VERSION ""

NS_ :

BS_:

BU_: Main_Module Torque_Vector Driveline Precharge Dashboard Steering Acceleration bootloader BMS_LV TESTER DAQ Precharge BMS1 TEST_NODE TEST_NODE_2 DAQ

BO_ 2214598913 main_hb: 2 Main_Module
 SG_ precharge_state : 8|1@1+ (1,0) [0|0] "" Vector__XXX
 SG_ car_state : 0|8@1+ (1,0) [0|0] "" Vector__XXX

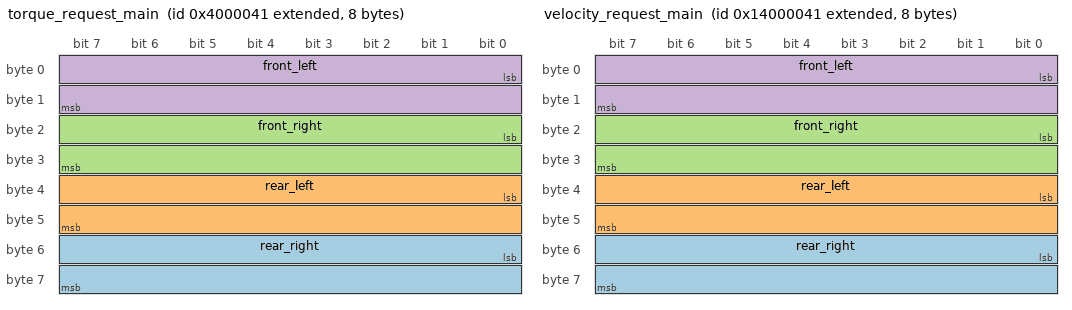
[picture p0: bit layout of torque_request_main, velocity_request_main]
BO_ 2214592577 torque_request_main: 8 Main_Module
 SG_ rear_right : 48|16@1- (1,0) [0|0] "" Vector__XXX
 SG_ rear_left : 32|16@1- (1,0) [0|0] "" Vector__XXX
 SG_ front_right : 16|16@1- (1,0) [0|0] "" Vector__XXX
 SG_ front_left : 0|16@1- (1,0) [0|0] "" Vector__XXX

BO_ 2483028033 velocity_request_main: 8 Main_Module
 SG_ rear_right : 48|16@1- (1,0) [0|0] "" Vector__XXX
 SG_ rear_left : 32|16@1- (1,0) [0|0] "" Vector__XXX
 SG_ front_right : 16|16@1- (1,0) [0|0] "" Vector__XXX
 SG_ front_left : 0|16@1- (1,0) [0|0] "" Vector__XXX

BO_ 2550136769 daq_response_MAIN_MODULE: 8 Main_Module
 SG_ daq_response : 0|64@1+ (1,0) [0|0] "" Vector__XXX

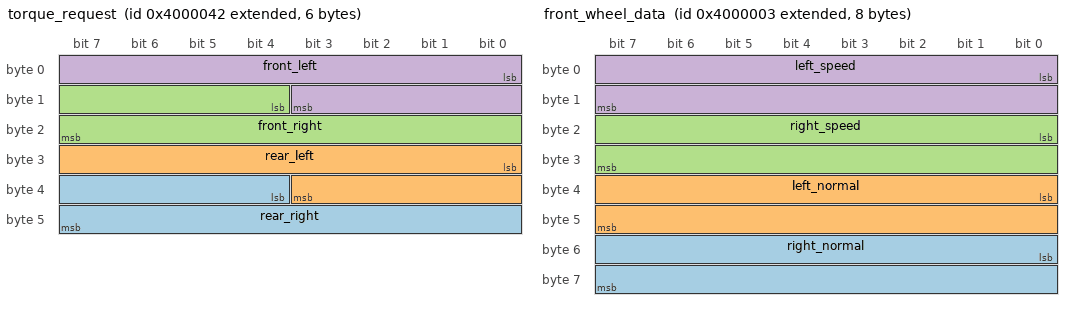
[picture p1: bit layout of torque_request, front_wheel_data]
BO_ 2214592578 torque_request: 6 Torque_Vector
 SG_ rear_right : 36|12@1+ (1,0) [0|0] "" Vector__XXX
 SG_ rear_left : 24|12@1+ (1,0) [0|0] "" Vector__XXX
 SG_ front_right : 12|12@1+ (1,0) [0|0] "" Vector__XXX
 SG_ front_left : 0|12@1+ (1,0) [0|0] "" Vector__XXX

BO_ 2147490050 bitstream_flash_status: 1 Torque_Vector
 SG_ flash_timeout_rx : 1|1@1+ (1,0) [0|0] "" Vector__XXX
 SG_ flash_success : 0|1@1+ (1,0) [0|0] "" Vector__XXX

BO_ 2214598915 front_driveline_hb: 2 Driveline
 SG_ front_right_motor : 8|8@1+ (1,0) [0|0] "" Vector__XXX
 SG_ front_left_motor : 0|8@1+ (1,0) [0|0] "" Vector__XXX

BO_ 2214598979 rear_driveline_hb: 2 Driveline
 SG_ rear_right_motor : 8|8@1+ (1,0) [0|0] "" Vector__XXX
 SG_ rear_left_motor : 0|8@1+ (1,0) [0|0] "" Vector__XXX

BO_ 2214592515 front_wheel_data: 8 Driveline
 SG_ right_normal : 48|16@1+ (1,0) [0|0] "" Vector__XXX
 SG_ left_normal : 32|16@1+ (1,0) [0|0] "" Vector__XXX
 SG_ right_speed : 16|16@1+ (1,0) [0|0] "kphx100" Vector__XXX
 SG_ left_speed : 0|16@1+ (1,0) [0|0] "kphx100" Vector__XXX

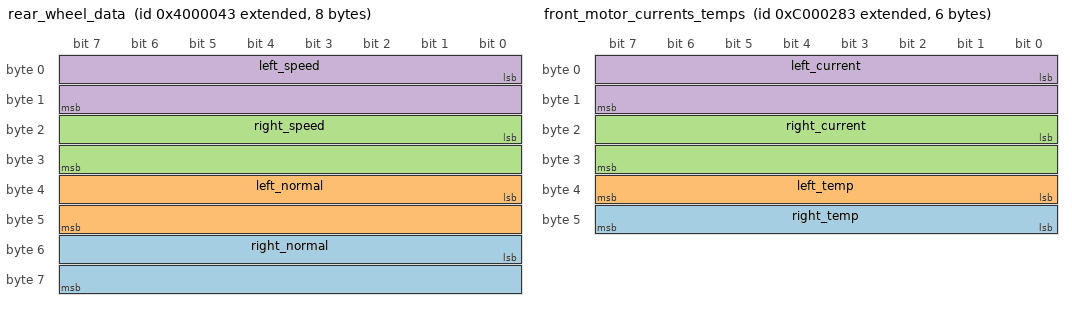
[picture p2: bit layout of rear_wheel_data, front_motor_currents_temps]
BO_ 2214592579 rear_wheel_data: 8 Driveline
 SG_ right_normal : 48|16@1+ (1,0) [0|0] "" Vector__XXX
 SG_ left_normal : 32|16@1+ (1,0) [0|0] "" Vector__XXX
 SG_ right_speed : 16|16@1+ (1,0) [0|0] "kphx100" Vector__XXX
 SG_ left_speed : 0|16@1+ (1,0) [0|0] "kphx100" Vector__XXX

BO_ 2348810883 front_motor_currents_temps: 6 Driveline
 SG_ right_temp : 40|8@1+ (1,0) [0|0] "C" Vector__XXX
 SG_ left_temp : 32|8@1+ (1,0) [0|0] "C" Vector__XXX
 SG_ right_current : 16|16@1+ (1,0) [0|0] "Ampx10" Vector__XXX
 SG_ left_current : 0|16@1+ (1,0) [0|0] "Ampx10" Vector__XXX

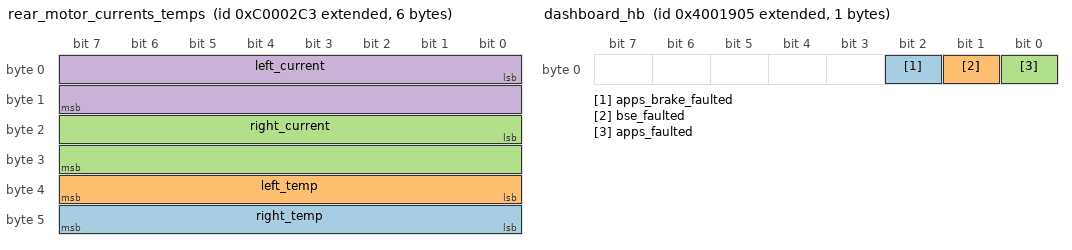
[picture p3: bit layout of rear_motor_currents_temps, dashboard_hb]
BO_ 2348810947 rear_motor_currents_temps: 6 Driveline
 SG_ right_temp : 40|8@1+ (1,0) [0|0] "C" Vector__XXX
 SG_ left_temp : 32|8@1+ (1,0) [0|0] "C" Vector__XXX
 SG_ right_current : 16|16@1+ (1,0) [0|0] "Ampx10" Vector__XXX
 SG_ left_current : 0|16@1+ (1,0) [0|0] "Ampx10" Vector__XXX

BO_ 2483028739 front_motor_init: 2 Driveline
 SG_ front_right_init : 8|8@1+ (1,0) [0|0] "" Vector__XXX
 SG_ front_left_init : 0|8@1+ (1,0) [0|0] "" Vector__XXX

BO_ 2483028803 rear_motor_init: 2 Driveline
 SG_ rear_right_init : 8|8@1+ (1,0) [0|0] "" Vector__XXX
 SG_ rear_left_init : 0|8@1+ (1,0) [0|0] "" Vector__XXX

BO_ 2281734148 test_precharge_msg: 1 Precharge
 SG_ test_precharge_sig : 0|8@1+ (1,0) [0|0] "" Vector__XXX

BO_ 2483028613 raw_throttle_brake: 3 Dashboard
 SG_ brake : 12|12@1+ (1,0) [0|0] "" Vector__XXX
 SG_ throttle : 0|12@1+ (1,0) [0|0] "" Vector__XXX

BO_ 2214592517 start_button: 1 Dashboard
 SG_ start : 0|1@1+ (1,0) [0|0] "" Vector__XXX

BO_ 2214598917 dashboard_hb: 1 Dashboard
 SG_ apps_brake_faulted : 2|1@1+ (1,0) [0|0] "" Vector__XXX
 SG_ bse_faulted : 1|1@1+ (1,0) [0|0] "" Vector__XXX
 SG_ apps_faulted : 0|1@1+ (1,0) [0|0] "" Vector__XXX

BO_ 2550136773 daq_response_DASHBOARD: 8 Dashboard
 SG_ daq_response : 0|64@1+ (1,0) [0|0] "" Vector__XXX

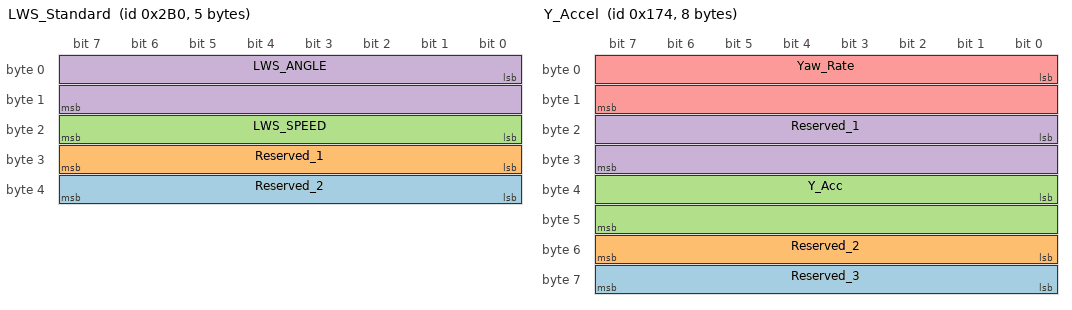
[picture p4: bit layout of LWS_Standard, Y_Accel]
BO_ 688 LWS_Standard: 5 Steering
 SG_ Reserved_2 : 32|8@1+ (1,0) [0|0] "" Vector__XXX
 SG_ Reserved_1 : 24|8@1+ (1,0) [0|0] "" Vector__XXX
 SG_ LWS_SPEED : 16|8@1+ (4,0) [0|0] "°/s" Vector__XXX
 SG_ LWS_ANGLE : 0|16@1- (0.1,0) [0|0] "°" Vector__XXX

BO_ 372 Y_Accel: 8 Acceleration
 SG_ Reserved_3 : 56|8@1+ (1,0) [0|0] "" Vector__XXX
 SG_ Reserved_2 : 48|8@1+ (1,0) [0|0] "" Vector__XXX
 SG_ Y_Acc : 32|16@1+ (0.0001274,-4.1746432) [0|0] "g" Vector__XXX
 SG_ Reserved_1 : 16|16@1+ (1,0) [0|0] "" Vector__XXX
 SG_ Yaw_Rate : 0|16@1+ (0.005,-163.84) [0|0] "°/s" Vector__XXX

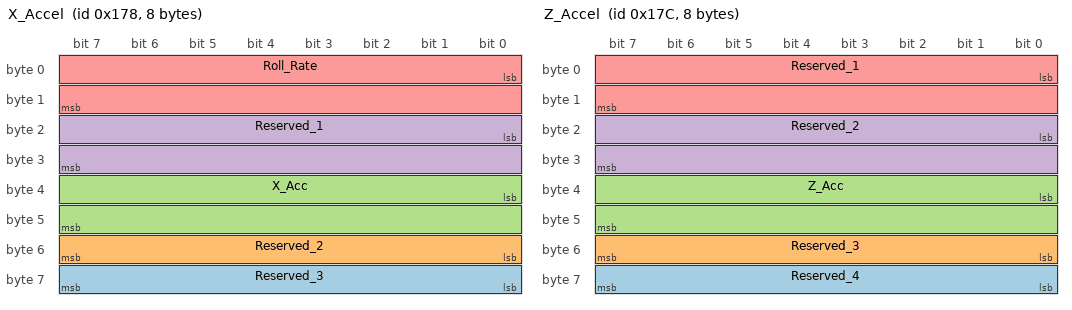
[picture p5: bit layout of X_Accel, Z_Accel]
BO_ 376 X_Accel: 8 Acceleration
 SG_ Reserved_3 : 56|8@1+ (1,0) [0|0] "" Vector__XXX
 SG_ Reserved_2 : 48|8@1+ (1,0) [0|0] "" Vector__XXX
 SG_ X_Acc : 32|16@1+ (0.0001274,-4.1746432) [0|0] "g" Vector__XXX
 SG_ Reserved_1 : 16|16@1+ (1,0) [0|0] "" Vector__XXX
 SG_ Roll_Rate : 0|16@1+ (0.005,-163.84) [0|0] "°/s" Vector__XXX

BO_ 380 Z_Accel: 8 Acceleration
 SG_ Reserved_4 : 56|8@1+ (1,0) [0|0] "" Vector__XXX
 SG_ Reserved_3 : 48|8@1+ (1,0) [0|0] "" Vector__XXX
 SG_ Z_Acc : 32|16@1+ (0.0001274,-4.1746432) [0|0] "g" Vector__XXX
 SG_ Reserved_2 : 16|16@1+ (1,0) [0|0] "" Vector__XXX
 SG_ Reserved_1 : 0|16@1+ (1,0) [0|0] "" Vector__XXX

BO_ 2214912572 mainmodule_bl_resp: 5 bootloader
 SG_ data : 8|32@1+ (1,0) [0|0] "" Vector__XXX
 SG_ cmd : 0|8@1+ (1,0) [0|0] "" Vector__XXX

BO_ 2214912636 dashboard_bl_resp: 5 bootloader
 SG_ data : 8|32@1+ (1,0) [0|0] "" Vector__XXX
 SG_ cmd : 0|8@1+ (1,0) [0|0] "" Vector__XXX

BO_ 2214912700 torquevector_bl_resp: 5 bootloader
 SG_ data : 8|32@1+ (1,0) [0|0] "" Vector__XXX
 SG_ cmd : 0|8@1+ (1,0) [0|0] "" Vector__XXX

BO_ 2214912764 driveline_f_bl_resp: 5 bootloader
 SG_ data : 8|32@1+ (1,0) [0|0] "" Vector__XXX
 SG_ cmd : 0|8@1+ (1,0) [0|0] "" Vector__XXX

BO_ 2214912828 driveline_r_bl_resp: 5 bootloader
 SG_ data : 8|32@1+ (1,0) [0|0] "" Vector__XXX
 SG_ cmd : 0|8@1+ (1,0) [0|0] "" Vector__XXX

BO_ 2214912892 precharge_bl_resp: 5 bootloader
 SG_ data : 8|32@1+ (1,0) [0|0] "" Vector__XXX
 SG_ cmd : 0|8@1+ (1,0) [0|0] "" Vector__XXX

BO_ 2214912956 bms_a_bl_resp: 5 bootloader
 SG_ data : 8|32@1+ (1,0) [0|0] "" Vector__XXX
 SG_ cmd : 0|8@1+ (1,0) [0|0] "" Vector__XXX

BO_ 2214913020 bms_b_bl_resp: 5 bootloader
 SG_ data : 8|32@1+ (1,0) [0|0] "" Vector__XXX
 SG_ cmd : 0|8@1+ (1,0) [0|0] "" Vector__XXX

BO_ 2214913084 bms_c_bl_resp: 5 bootloader
 SG_ data : 8|32@1+ (1,0) [0|0] "" Vector__XXX
 SG_ cmd : 0|8@1+ (1,0) [0|0] "" Vector__XXX

BO_ 2214913148 bms_d_bl_resp: 5 bootloader
 SG_ data : 8|32@1+ (1,0) [0|0] "" Vector__XXX
 SG_ cmd : 0|8@1+ (1,0) [0|0] "" Vector__XXX

BO_ 2214913212 bms_e_bl_resp: 5 bootloader
 SG_ data : 8|32@1+ (1,0) [0|0] "" Vector__XXX
 SG_ cmd : 0|8@1+ (1,0) [0|0] "" Vector__XXX

BO_ 2214913276 bms_f_bl_resp: 5 bootloader
 SG_ data : 8|32@1+ (1,0) [0|0] "" Vector__XXX
 SG_ cmd : 0|8@1+ (1,0) [0|0] "" Vector__XXX

BO_ 2214913340 bms_g_bl_resp: 5 bootloader
 SG_ data : 8|32@1+ (1,0) [0|0] "" Vector__XXX
 SG_ cmd : 0|8@1+ (1,0) [0|0] "" Vector__XXX

BO_ 2214913404 bms_h_bl_resp: 5 bootloader
 SG_ data : 8|32@1+ (1,0) [0|0] "" Vector__XXX
 SG_ cmd : 0|8@1+ (1,0) [0|0] "" Vector__XXX

BO_ 2214913468 bms_i_bl_resp: 5 bootloader
 SG_ data : 8|32@1+ (1,0) [0|0] "" Vector__XXX
 SG_ cmd : 0|8@1+ (1,0) [0|0] "" Vector__XXX

BO_ 2214913532 bms_j_bl_resp: 5 bootloader
 SG_ data : 8|32@1+ (1,0) [0|0] "" Vector__XXX
 SG_ cmd : 0|8@1+ (1,0) [0|0] "" Vector__XXX

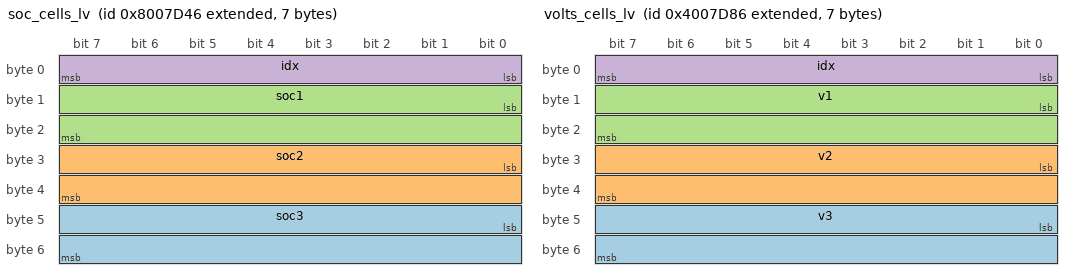
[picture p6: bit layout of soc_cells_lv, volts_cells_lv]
BO_ 2281733446 soc_cells_lv: 7 BMS_LV
 SG_ soc3 : 40|16@1+ (1,0) [0|0] "" Vector__XXX
 SG_ soc2 : 24|16@1+ (1,0) [0|0] "" Vector__XXX
 SG_ soc1 : 8|16@1+ (1,0) [0|0] "" Vector__XXX
 SG_ idx : 0|8@1+ (1,0) [0|0] "" Vector__XXX

BO_ 2214624646 volts_cells_lv: 7 BMS_LV
 SG_ v3 : 40|16@1+ (1,0) [0|0] "" Vector__XXX
 SG_ v2 : 24|16@1+ (1,0) [0|0] "" Vector__XXX
 SG_ v1 : 8|16@1+ (1,0) [0|0] "" Vector__XXX
 SG_ idx : 0|8@1+ (1,0) [0|0] "" Vector__XXX

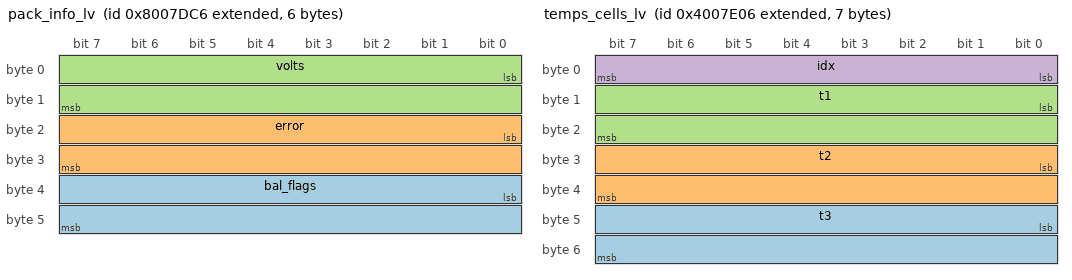
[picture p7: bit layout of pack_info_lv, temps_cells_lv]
BO_ 2281733574 pack_info_lv: 6 BMS_LV
 SG_ bal_flags : 32|16@1+ (1,0) [0|0] "" Vector__XXX
 SG_ error : 16|16@1+ (1,0) [0|0] "" Vector__XXX
 SG_ volts : 0|16@1+ (1,0) [0|0] "" Vector__XXX

BO_ 2214624774 temps_cells_lv: 7 BMS_LV
 SG_ t3 : 40|16@1+ (1,0) [0|0] "" Vector__XXX
 SG_ t2 : 24|16@1+ (1,0) [0|0] "" Vector__XXX
 SG_ t1 : 8|16@1+ (1,0) [0|0] "" Vector__XXX
 SG_ idx : 0|8@1+ (1,0) [0|0] "" Vector__XXX

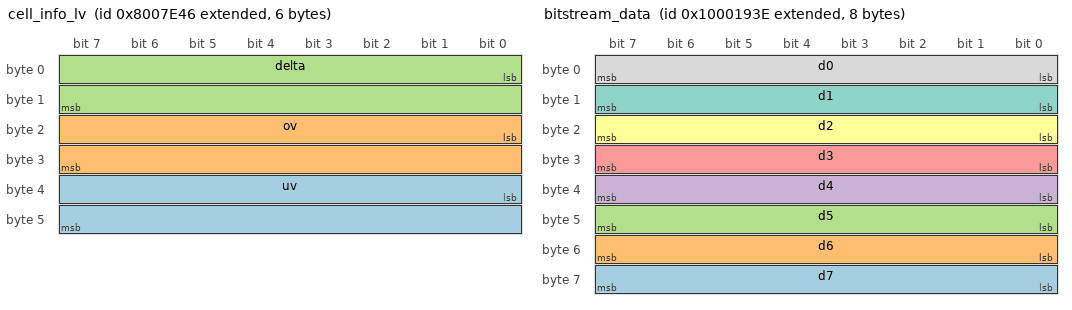
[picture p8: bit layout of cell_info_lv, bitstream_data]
BO_ 2281733702 cell_info_lv: 6 BMS_LV
 SG_ uv : 32|16@1+ (1,0) [0|0] "" Vector__XXX
 SG_ ov : 16|16@1+ (1,0) [0|0] "" Vector__XXX
 SG_ delta : 0|16@1+ (1,0) [0|0] "" Vector__XXX

BO_ 2214624902 power_lim_lv: 4 BMS_LV
 SG_ chg_lim : 16|16@1+ (1,0) [0|0] "" Vector__XXX
 SG_ disch_lim : 0|16@1+ (1,0) [0|0] "" Vector__XXX

BO_ 2282341438 bootloader_request_reset: 1 TESTER
 SG_ node : 0|8@1+ (1,0) [0|0] "" Vector__XXX

BO_ 2415925566 bitstream_data: 8 TESTER
 SG_ d7 : 56|8@1+ (1,0) [0|0] "" Vector__XXX
 SG_ d6 : 48|8@1+ (1,0) [0|0] "" Vector__XXX
 SG_ d5 : 40|8@1+ (1,0) [0|0] "" Vector__XXX
 SG_ d4 : 32|8@1+ (1,0) [0|0] "" Vector__XXX
 SG_ d3 : 24|8@1+ (1,0) [0|0] "" Vector__XXX
 SG_ d2 : 16|8@1+ (1,0) [0|0] "" Vector__XXX
 SG_ d1 : 8|8@1+ (1,0) [0|0] "" Vector__XXX
 SG_ d0 : 0|8@1+ (1,0) [0|0] "" Vector__XXX

BO_ 2415925630 bitstream_request: 5 TESTER
 SG_ download_size : 1|32@1+ (1,0) [0|0] "" Vector__XXX
 SG_ download_request : 0|1@1+ (1,0) [0|0] "" Vector__XXX

BO_ 2215232574 mainmodule_bl_cmd: 5 TESTER
 SG_ data : 8|32@1+ (1,0) [0|0] "" Vector__XXX
 SG_ cmd : 0|8@1+ (1,0) [0|0] "" Vector__XXX

BO_ 2215232638 dashboard_bl_cmd: 5 TESTER
 SG_ data : 8|32@1+ (1,0) [0|0] "" Vector__XXX
 SG_ cmd : 0|8@1+ (1,0) [0|0] "" Vector__XXX

BO_ 2215232702 torquevector_bl_cmd: 5 TESTER
 SG_ data : 8|32@1+ (1,0) [0|0] "" Vector__XXX
 SG_ cmd : 0|8@1+ (1,0) [0|0] "" Vector__XXX

BO_ 2215232766 driveline_f_bl_cmd: 5 TESTER
 SG_ data : 8|32@1+ (1,0) [0|0] "" Vector__XXX
 SG_ cmd : 0|8@1+ (1,0) [0|0] "" Vector__XXX

BO_ 2215232830 driveline_r_bl_cmd: 5 TESTER
 SG_ data : 8|32@1+ (1,0) [0|0] "" Vector__XXX
 SG_ cmd : 0|8@1+ (1,0) [0|0] "" Vector__XXX

BO_ 2215232894 precharge_bl_cmd: 5 TESTER
 SG_ data : 8|32@1+ (1,0) [0|0] "" Vector__XXX
 SG_ cmd : 0|8@1+ (1,0) [0|0] "" Vector__XXX

BO_ 2215232958 bms_a_bl_cmd: 5 TESTER
 SG_ data : 8|32@1+ (1,0) [0|0] "" Vector__XXX
 SG_ cmd : 0|8@1+ (1,0) [0|0] "" Vector__XXX

BO_ 2215233022 bms_b_bl_cmd: 5 TESTER
 SG_ data : 8|32@1+ (1,0) [0|0] "" Vector__XXX
 SG_ cmd : 0|8@1+ (1,0) [0|0] "" Vector__XXX

BO_ 2215233086 bms_c_bl_cmd: 5 TESTER
 SG_ data : 8|32@1+ (1,0) [0|0] "" Vector__XXX
 SG_ cmd : 0|8@1+ (1,0) [0|0] "" Vector__XXX

BO_ 2215233150 bms_d_bl_cmd: 5 TESTER
 SG_ data : 8|32@1+ (1,0) [0|0] "" Vector__XXX
 SG_ cmd : 0|8@1+ (1,0) [0|0] "" Vector__XXX

BO_ 2215233214 bms_e_bl_cmd: 5 TESTER
 SG_ data : 8|32@1+ (1,0) [0|0] "" Vector__XXX
 SG_ cmd : 0|8@1+ (1,0) [0|0] "" Vector__XXX

BO_ 2215233278 bms_f_bl_cmd: 5 TESTER
 SG_ data : 8|32@1+ (1,0) [0|0] "" Vector__XXX
 SG_ cmd : 0|8@1+ (1,0) [0|0] "" Vector__XXX

BO_ 2215233342 bms_g_bl_cmd: 5 TESTER
 SG_ data : 8|32@1+ (1,0) [0|0] "" Vector__XXX
 SG_ cmd : 0|8@1+ (1,0) [0|0] "" Vector__XXX

BO_ 2215233406 bms_h_bl_cmd: 5 TESTER
 SG_ data : 8|32@1+ (1,0) [0|0] "" Vector__XXX
 SG_ cmd : 0|8@1+ (1,0) [0|0] "" Vector__XXX

BO_ 2215233470 bms_i_bl_cmd: 5 TESTER
 SG_ data : 8|32@1+ (1,0) [0|0] "" Vector__XXX
 SG_ cmd : 0|8@1+ (1,0) [0|0] "" Vector__XXX

BO_ 2215233534 bms_j_bl_cmd: 5 TESTER
 SG_ data : 8|32@1+ (1,0) [0|0] "" Vector__XXX
 SG_ cmd : 0|8@1+ (1,0) [0|0] "" Vector__XXX

BO_ 2483028082 daq_command_MAIN_MODULE: 8 DAQ
 SG_ daq_command : 0|64@1+ (1,0) [0|0] "" Vector__XXX

BO_ 2483028338 daq_command_DASHBOARD: 8 DAQ
 SG_ daq_command : 0|64@1+ (1,0) [0|0] "" Vector__XXX

BO_ 2281733418 heat_req: 3 Precharge
 SG_ time : 1|16@1+ (1,0) [0|0] "" Vector__XXX
 SG_ toggle : 0|1@1+ (1,0) [0|0] "" Vector__XXX

BO_ 2214624618 pack_curr: 2 Precharge
 SG_ current : 0|16@1- (1,0) [0|0] "" Vector__XXX

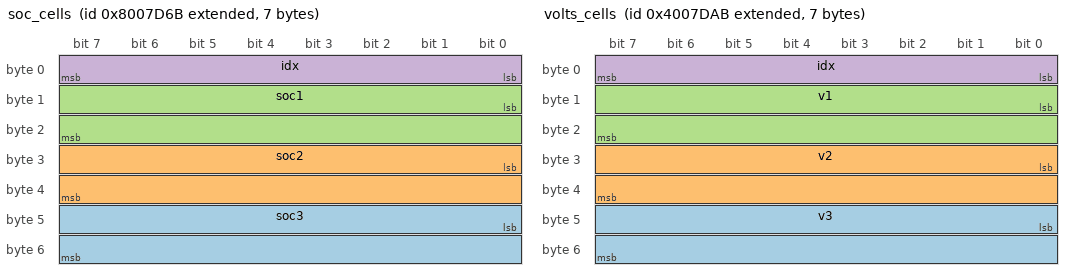
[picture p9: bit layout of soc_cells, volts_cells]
BO_ 2281733483 soc_cells: 7 BMS1
 SG_ soc3 : 40|16@1+ (1,0) [0|0] "" Vector__XXX
 SG_ soc2 : 24|16@1+ (1,0) [0|0] "" Vector__XXX
 SG_ soc1 : 8|16@1+ (1,0) [0|0] "" Vector__XXX
 SG_ idx : 0|8@1+ (1,0) [0|0] "" Vector__XXX

BO_ 2214624683 volts_cells: 7 BMS1
 SG_ v3 : 40|16@1+ (1,0) [0|0] "" Vector__XXX
 SG_ v2 : 24|16@1+ (1,0) [0|0] "" Vector__XXX
 SG_ v1 : 8|16@1+ (1,0) [0|0] "" Vector__XXX
 SG_ idx : 0|8@1+ (1,0) [0|0] "" Vector__XXX

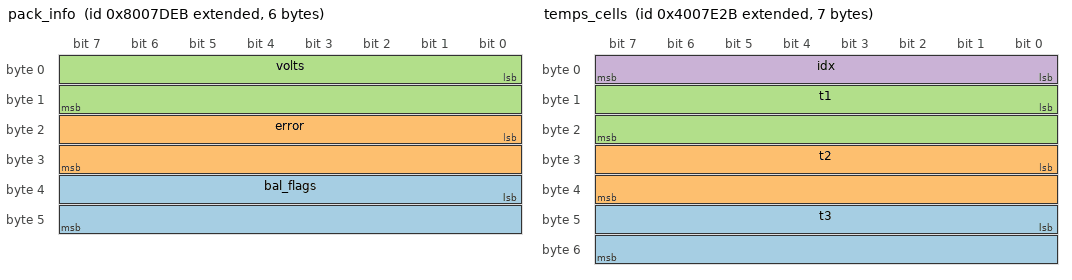
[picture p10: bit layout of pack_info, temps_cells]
BO_ 2281733611 pack_info: 6 BMS1
 SG_ bal_flags : 32|16@1+ (1,0) [0|0] "" Vector__XXX
 SG_ error : 16|16@1+ (1,0) [0|0] "" Vector__XXX
 SG_ volts : 0|16@1+ (1,0) [0|0] "" Vector__XXX

BO_ 2214624811 temps_cells: 7 BMS1
 SG_ t3 : 40|16@1+ (1,0) [0|0] "" Vector__XXX
 SG_ t2 : 24|16@1+ (1,0) [0|0] "" Vector__XXX
 SG_ t1 : 8|16@1+ (1,0) [0|0] "" Vector__XXX
 SG_ idx : 0|8@1+ (1,0) [0|0] "" Vector__XXX

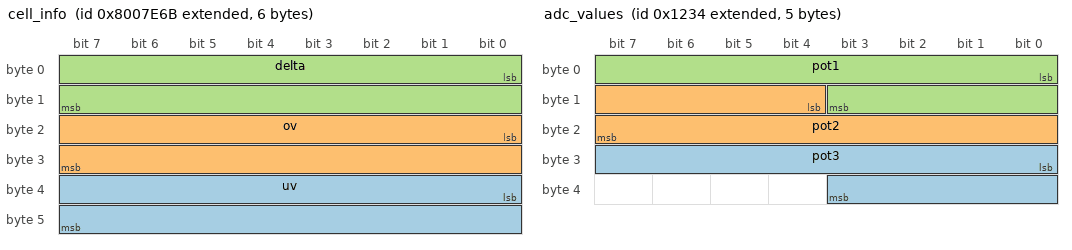
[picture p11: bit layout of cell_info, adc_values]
BO_ 2281733739 cell_info: 6 BMS1
 SG_ uv : 32|16@1+ (1,0) [0|0] "" Vector__XXX
 SG_ ov : 16|16@1+ (1,0) [0|0] "" Vector__XXX
 SG_ delta : 0|16@1+ (1,0) [0|0] "" Vector__XXX

BO_ 2214624939 power_lim: 4 BMS1
 SG_ chg_lim : 16|16@1+ (1,0) [0|0] "" Vector__XXX
 SG_ disch_lim : 0|16@1+ (1,0) [0|0] "" Vector__XXX

BO_ 2483028095 test_msg: 2 TEST_NODE
 SG_ test_sig : 0|16@1- (1,0) [0|0] "" Vector__XXX

BO_ 2483028159 test_msg2: 2 TEST_NODE
 SG_ test_sig2 : 0|16@1+ (1,0) [0|0] "" Vector__XXX

BO_ 2483028223 test_msg3: 2 TEST_NODE
 SG_ test_sig3 : 0|16@1+ (1,0) [0|0] "" Vector__XXX

BO_ 2483028287 test_msg4: 2 TEST_NODE
 SG_ test_sig4 : 0|16@1+ (1,0) [0|0] "" Vector__XXX

BO_ 2483028351 test_msg5: 2 TEST_NODE
 SG_ test_sig5 : 0|16@1+ (1,0) [0|0] "" Vector__XXX

BO_ 2348810751 wheel_speeds: 8 TEST_NODE
 SG_ right_speed : 32|32@1- (1,0) [0|0] "kph" Vector__XXX
 SG_ left_speed : 0|32@1- (1,0) [0|0] "kph" Vector__XXX

BO_ 2147488308 adc_values: 5 TEST_NODE
 SG_ pot3 : 24|12@1+ (1,0) [0|0] "" Vector__XXX
 SG_ pot2 : 12|12@1+ (1,0) [0|0] "" Vector__XXX
 SG_ pot1 : 0|12@1+ (1,0) [0|0] "" Vector__XXX

BO_ 2347693088 car_state: 1 TEST_NODE
 SG_ car_state : 0|8@1+ (1,0) [0|0] "" Vector__XXX

BO_ 2550136831 daq_response_TEST_NODE: 8 TEST_NODE
 SG_ daq_response : 0|64@1+ (1,0) [0|0] "" Vector__XXX

BO_ 2483028093 test_msg_2: 2 TEST_NODE_2
 SG_ test_sig : 0|16@1+ (1,0) [0|0] "" Vector__XXX

BO_ 2483028157 test_msg2_2: 2 TEST_NODE_2
 SG_ test_sig2 : 0|16@1+ (1,0) [0|0] "" Vector__XXX

BO_ 2483028221 test_msg3_2: 2 TEST_NODE_2
 SG_ test_sig3 : 0|16@1+ (1,0) [0|0] "" Vector__XXX

BO_ 2483028285 test_msg4_2: 2 TEST_NODE_2
 SG_ test_sig4 : 0|16@1+ (1,0) [0|0] "" Vector__XXX

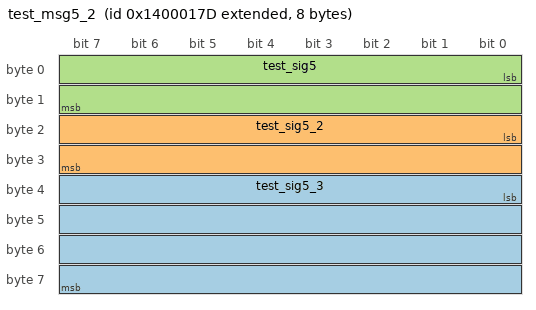
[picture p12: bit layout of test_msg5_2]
BO_ 2483028349 test_msg5_2: 8 TEST_NODE_2
 SG_ test_sig5_3 : 32|32@1- (1,0) [0|0] "" Vector__XXX
 SG_ test_sig5_2 : 16|16@1- (1,0) [0|0] "" Vector__XXX
 SG_ test_sig5 : 0|16@1+ (1,0) [0|0] "" Vector__XXX

BO_ 2147492386 test_stale: 1 TEST_NODE_2
 SG_ data : 0|8@1+ (1,0) [0|0] "" Vector__XXX

BO_ 2347693089 car_state2: 1 TEST_NODE_2
 SG_ car_state2 : 0|8@1+ (1,0) [0|0] "" Vector__XXX

BO_ 2550136829 daq_response_TEST_NODE_2: 8 TEST_NODE_2
 SG_ daq_response : 0|64@1+ (1,0) [0|0] "" Vector__XXX

BO_ 2483032050 daq_command_TEST_NODE: 8 DAQ
 SG_ daq_command : 0|64@1+ (1,0) [0|0] "" Vector__XXX

BO_ 2483031922 daq_command_TEST_NODE_2: 8 DAQ
 SG_ daq_command : 0|64@1+ (1,0) [0|0] "" Vector__XXX

CM_ BO_ 2214598913 "Heart beat message for main module";
CM_ SG_ 2214598913 precharge_state "Precharge complete state";
CM_ SG_ 2214598913 car_state "Main car state";
CM_ BO_ 2214592577 "Torque request for all motors, temporarily from main.";
CM_ SG_ 2214592577 rear_right "torque request. -4095-4095";
CM_ SG_ 2214592577 rear_left "torque request. -4095-4095";
CM_ SG_ 2214592577 front_right "torque request. -4095-4095";
CM_ SG_ 2214592577 front_left "torque request. -4095-4095";
CM_ BO_ 2483028033 "Test of E-Diff to see velocity outputs given wheel input";
CM_ SG_ 2483028033 rear_right "velocity request * 10";
CM_ SG_ 2483028033 rear_left "velocity request * 10";
CM_ SG_ 2483028033 front_right "velocity request * 10";
CM_ SG_ 2483028033 front_left "velocity request * 10";
CM_ BO_ 2550136769 "daq response from node MAIN_MODULE";
CM_ BO_ 2214592578 "Torque request for all motors.";
CM_ SG_ 2214592578 rear_right "torque request. 0-4096";
CM_ SG_ 2214592578 rear_left "torque request. 0-4096";
CM_ SG_ 2214592578 front_right "torque request. 0-4096";
CM_ SG_ 2214592578 front_left "torque request. 0-4096";
CM_ BO_ 2147490050 "Status message for bitstream flashing";
CM_ SG_ 2147490050 flash_timeout_rx "Timeout from CAN rx";
CM_ SG_ 2147490050 flash_success "Done flashing bitstream";
CM_ BO_ 2214598915 "front drivline heart beat";
CM_ BO_ 2214598979 "rear drivline heart beat";
CM_ BO_ 2214592515 "Wheel data for the rear tires";
CM_ BO_ 2214592579 "Wheel data for the rear tires";
CM_ BO_ 2348810883 "DC Current and Temperature of the motor controllers";
CM_ BO_ 2348810947 "DC Current and Temperature of the motor controllers";
CM_ BO_ 2483028739 "Front motor controller initialization status";
CM_ BO_ 2483028803 "Front motor controller initialization status";
CM_ BO_ 2281734148 "test precharge desc";
CM_ BO_ 2483028613 "throttle_brake desc";
CM_ BO_ 2214592517 "Car start button pressed";
CM_ BO_ 2214598917 "periodic dashboard heartbeat";
CM_ BO_ 2550136773 "daq response from node DASHBOARD";
CM_ BO_ 688 "Standard steering angle and speed";
CM_ BO_ 372 "Y Acceleration Update";
CM_ BO_ 376 "X Acceleration Update";
CM_ BO_ 380 "Z Acceleration Update";
CM_ BO_ 2214912572 "Main Module Bootloader response";
CM_ BO_ 2214912636 "Dashboard Bootloader response";
CM_ BO_ 2214912700 "Torque Vector Bootloader response";
CM_ BO_ 2214912764 "Torque Vector Bootloader response";
CM_ BO_ 2214912828 "Torque Vector Bootloader response";
CM_ BO_ 2214912892 "Torque Vector Bootloader response";
CM_ BO_ 2214912956 "Torque Vector Bootloader response";
CM_ BO_ 2214913020 "Torque Vector Bootloader response";
CM_ BO_ 2214913084 "Torque Vector Bootloader response";
CM_ BO_ 2214913148 "Torque Vector Bootloader response";
CM_ BO_ 2214913212 "Torque Vector Bootloader response";
CM_ BO_ 2214913276 "Torque Vector Bootloader response";
CM_ BO_ 2214913340 "Torque Vector Bootloader response";
CM_ BO_ 2214913404 "Torque Vector Bootloader response";
CM_ BO_ 2214913468 "Torque Vector Bootloader response";
CM_ BO_ 2214913532 "Torque Vector Bootloader response";
CM_ BO_ 2281733446 "Estimated soc";
CM_ SG_ 2281733446 soc3 "Cell 2 in % * 100";
CM_ SG_ 2281733446 soc2 "Cell 1 in % * 100";
CM_ SG_ 2281733446 soc1 "Cell 0 in % * 100";
CM_ SG_ 2281733446 idx "Index of each set";
CM_ BO_ 2214624646 "Measured cell voltages";
CM_ SG_ 2214624646 v3 "Cell 2 in V * 10000";
CM_ SG_ 2214624646 v2 "Cell 1 in V * 10000";
CM_ SG_ 2214624646 v1 "Cell 0 in V * 10000";
CM_ SG_ 2214624646 idx "Index of each set";
CM_ BO_ 2281733574 "Pack information";
CM_ SG_ 2281733574 bal_flags "Balance flags. 1 for on";
CM_ SG_ 2281733574 error "Error flags (non-zero is fault)";
CM_ SG_ 2281733574 volts "Pack voltage in V * 10000";
CM_ BO_ 2214624774 "Measured cell temperatures";
CM_ SG_ 2214624774 t3 "Cell 2 in deg C * 10000";
CM_ SG_ 2214624774 t2 "Cell 1 in deg C * 10000";
CM_ SG_ 2214624774 t1 "Cell 0 in deg C * 10000";
CM_ SG_ 2214624774 idx "Index of each set";
CM_ BO_ 2281733702 "Cell information";
CM_ SG_ 2281733702 uv "Under-voltage flags. 1 for fault";
CM_ SG_ 2281733702 ov "Over-voltage flags. 1 for fault";
CM_ SG_ 2281733702 delta "Max cell delta in V * 10000";
CM_ BO_ 2214624902 "Power limits";
CM_ SG_ 2214624902 chg_lim "Charge limit in W";
CM_ SG_ 2214624902 disch_lim "Discharge limit in W";
CM_ BO_ 2282341438 "Request message for resetting a node for bootloader download";
CM_ SG_ 2282341438 node "Target node to reset";
CM_ BO_ 2415925566 "Bitstream download command";
CM_ SG_ 2415925566 d7 "Bitstream data word 7";
CM_ SG_ 2415925566 d6 "Bitstream data word 6";
CM_ SG_ 2415925566 d5 "Bitstream data word 5";
CM_ SG_ 2415925566 d4 "Bitstream data word 4";
CM_ SG_ 2415925566 d3 "Bitstream data word 3";
CM_ SG_ 2415925566 d2 "Bitstream data word 2";
CM_ SG_ 2415925566 d1 "Bitstream data word 1";
CM_ SG_ 2415925566 d0 "Bitstream data word 0";
CM_ BO_ 2415925630 "Bitstream state command";
CM_ SG_ 2415925630 download_size "size for expected bitstream download (bytes)";
CM_ SG_ 2415925630 download_request "Request to download new bitstream";
CM_ BO_ 2215232574 "Bootloader command for main module";
CM_ SG_ 2215232574 data "Bootloader data";
CM_ SG_ 2215232574 cmd "Bootloader Command type";
CM_ BO_ 2215232638 "Bootloader command for dashboard";
CM_ SG_ 2215232638 data "Bootloader data";
CM_ SG_ 2215232638 cmd "Bootloader Command type";
CM_ BO_ 2215232702 "Bootloader command for torque vector";
CM_ SG_ 2215232702 data "Bootloader data";
CM_ SG_ 2215232702 cmd "Bootloader Command type";
CM_ BO_ 2215232766 "Bootloader command for torque vector";
CM_ SG_ 2215232766 data "Bootloader data";
CM_ SG_ 2215232766 cmd "Bootloader Command type";
CM_ BO_ 2215232830 "Bootloader command for torque vector";
CM_ SG_ 2215232830 data "Bootloader data";
CM_ SG_ 2215232830 cmd "Bootloader Command type";
CM_ BO_ 2215232894 "Bootloader command for torque vector";
CM_ SG_ 2215232894 data "Bootloader data";
CM_ SG_ 2215232894 cmd "Bootloader Command type";
CM_ BO_ 2215232958 "Bootloader command for torque vector";
CM_ SG_ 2215232958 data "Bootloader data";
CM_ SG_ 2215232958 cmd "Bootloader Command type";
CM_ BO_ 2215233022 "Bootloader command for torque vector";
CM_ SG_ 2215233022 data "Bootloader data";
CM_ SG_ 2215233022 cmd "Bootloader Command type";
CM_ BO_ 2215233086 "Bootloader command for torque vector";
CM_ SG_ 2215233086 data "Bootloader data";
CM_ SG_ 2215233086 cmd "Bootloader Command type";
CM_ BO_ 2215233150 "Bootloader command for torque vector";
CM_ SG_ 2215233150 data "Bootloader data";
CM_ SG_ 2215233150 cmd "Bootloader Command type";
CM_ BO_ 2215233214 "Bootloader command for torque vector";
CM_ SG_ 2215233214 data "Bootloader data";
CM_ SG_ 2215233214 cmd "Bootloader Command type";
CM_ BO_ 2215233278 "Bootloader command for torque vector";
CM_ SG_ 2215233278 data "Bootloader data";
CM_ SG_ 2215233278 cmd "Bootloader Command type";
CM_ BO_ 2215233342 "Bootloader command for torque vector";
CM_ SG_ 2215233342 data "Bootloader data";
CM_ SG_ 2215233342 cmd "Bootloader Command type";
CM_ BO_ 2215233406 "Bootloader command for torque vector";
CM_ SG_ 2215233406 data "Bootloader data";
CM_ SG_ 2215233406 cmd "Bootloader Command type";
CM_ BO_ 2215233470 "Bootloader command for torque vector";
CM_ SG_ 2215233470 data "Bootloader data";
CM_ SG_ 2215233470 cmd "Bootloader Command type";
CM_ BO_ 2215233534 "Bootloader command for torque vector";
CM_ SG_ 2215233534 data "Bootloader data";
CM_ SG_ 2215233534 cmd "Bootloader Command type";
CM_ BO_ 2483028082 "daq command for node MAIN_MODULE";
CM_ BO_ 2483028338 "daq command for node DASHBOARD";
CM_ BO_ 2281733418 "Starts BMS pre-heat for set time";
CM_ SG_ 2281733418 time "Set runtime in ms";
CM_ SG_ 2281733418 toggle "1 for start, 0 for stop";
CM_ BO_ 2214624618 "Pack current";
CM_ SG_ 2214624618 current "Pack current";
CM_ BO_ 2281733483 "Estimated soc";
CM_ SG_ 2281733483 soc3 "Cell 2 in % * 100";
CM_ SG_ 2281733483 soc2 "Cell 1 in % * 100";
CM_ SG_ 2281733483 soc1 "Cell 0 in % * 100";
CM_ SG_ 2281733483 idx "Index of each set";
CM_ BO_ 2214624683 "Measured cell voltages";
CM_ SG_ 2214624683 v3 "Cell 2 in V * 10000";
CM_ SG_ 2214624683 v2 "Cell 1 in V * 10000";
CM_ SG_ 2214624683 v1 "Cell 0 in V * 10000";
CM_ SG_ 2214624683 idx "Index of each set";
CM_ BO_ 2281733611 "Pack information";
CM_ SG_ 2281733611 bal_flags "Balance flags. 1 for on";
CM_ SG_ 2281733611 error "Error flags (non-zero is fault)";
CM_ SG_ 2281733611 volts "Pack voltage in V * 10000";
CM_ BO_ 2214624811 "Measured cell temperatures";
CM_ SG_ 2214624811 t3 "Cell 2 in deg C * 10000";
CM_ SG_ 2214624811 t2 "Cell 1 in deg C * 10000";
CM_ SG_ 2214624811 t1 "Cell 0 in deg C * 10000";
CM_ SG_ 2214624811 idx "Index of each set";
CM_ BO_ 2281733739 "Cell information";
CM_ SG_ 2281733739 uv "Under-voltage flags. 1 for fault";
CM_ SG_ 2281733739 ov "Over-voltage flags. 1 for fault";
CM_ SG_ 2281733739 delta "Max cell delta in V * 10000";
CM_ BO_ 2214624939 "Power limits";
CM_ SG_ 2214624939 chg_lim "Charge limit in W";
CM_ SG_ 2214624939 disch_lim "Discharge limit in W";
CM_ BO_ 2483028095 "test_msg desc";
CM_ BO_ 2483028159 "test_msg2 desc";
CM_ BO_ 2483028223 "test_msg2 desc";
CM_ BO_ 2483028287 "test_msg4 desc";
CM_ BO_ 2483028351 "test_msg5 desc";
CM_ BO_ 2348810751 "wheel speeds";
CM_ BO_ 2147488308 "adc potentiometer readings";
CM_ BO_ 2347693088 "state of the car";
CM_ BO_ 2550136831 "daq response from node TEST_NODE";
CM_ BO_ 2483028093 "test_msg desc";
CM_ BO_ 2483028157 "test_msg2 desc";
CM_ BO_ 2483028221 "test_msg2 desc";
CM_ BO_ 2483028285 "test_msg4 desc";
CM_ BO_ 2483028349 "test_msg5 desc";
CM_ BO_ 2147492386 "used to test stale";
CM_ BO_ 2347693089 "state of the car";
CM_ BO_ 2550136829 "daq response from node TEST_NODE_2";
CM_ BO_ 2483032050 "daq command for node TEST_NODE";
CM_ BO_ 2483031922 "daq command for node TEST_NODE_2";

VAL_ 2214598913 car_state 0 "init" 1 "buzzing" 2 "ready2drive" 3 "error" 4 "fatal" 5 "reset" 6 "recover" ;
VAL_ 2214598915 front_right_motor 0 "disconnected" 1 "initializing" 2 "connected" 3 "error" ;
VAL_ 2214598915 front_left_motor 0 "disconnected" 1 "initializing" 2 "connected" 3 "error" ;
VAL_ 2214598979 rear_right_motor 0 "disconnected" 1 "initializaing" 2 "connected" 3 "error" ;
VAL_ 2214598979 rear_left_motor 0 "disconnected" 1 "initializing" 2 "connected" 3 "error" ;
VAL_ 2483028739 front_right_init 0 "starting" 1 "waiting" 2 "delaying" 3 "failed" 4 "connected" ;
VAL_ 2483028739 front_left_init 0 "starting" 1 "waiting" 2 "delaying" 3 "failed" 4 "connected" ;
VAL_ 2483028803 rear_right_init 0 "starting" 1 "waiting" 2 "delaying" 3 "failed" 4 "connected" ;
VAL_ 2483028803 rear_left_init 0 "starting" 1 "waiting" 2 "delaying" 3 "failed" 4 "connected" ;
VAL_ 2347693088 car_state 0 "ready2go" 1 "flipped" 2 "flying" 3 "lightspeed" ;
VAL_ 2347693089 car_state2 0 "ready2go" 1 "flipped" 2 "flying" 3 "lightspeed" ;
SIG_VALTYPE_ 2348810751 left_speed : 1;
SIG_VALTYPE_ 2348810751 right_speed : 1;
SIG_VALTYPE_ 2483028349 test_sig5_3 : 1;
